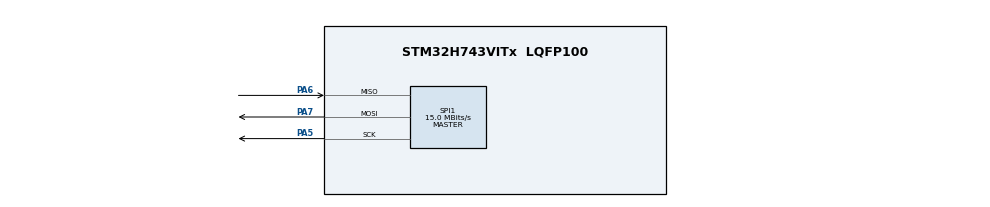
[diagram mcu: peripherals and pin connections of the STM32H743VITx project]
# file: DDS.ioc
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Mcu.Family=STM32H7
Mcu.Name=STM32H743VITx
Mcu.Package=LQFP100
NVIC.PriorityGroup=NVIC_PRIORITYGROUP_4
PA5.Mode=Full_Duplex_Master
PA5.Signal=SPI1_SCK
PA6.Mode=Full_Duplex_Master
PA6.Signal=SPI1_MISO
PA7.Mode=Full_Duplex_Master
PA7.Signal=SPI1_MOSI
PH0-OSC_IN\ (PH0).Mode=HSE-External-Oscillator
PH0-OSC_IN\ (PH0).Signal=RCC_OSC_IN
PH1-OSC_OUT\ (PH1).Mode=HSE-External-Oscillator
PH1-OSC_OUT\ (PH1).Signal=RCC_OSC_OUT
ProjectManager.HeapSize=0x200
ProjectManager.StackSize=0x400
ProjectManager.TargetToolchain=MDK-ARM V5
RCC.ADCFreq_Value=16125000
RCC.APB1Freq_Value=120000000
RCC.APB2Freq_Value=120000000
RCC.APB3Freq_Value=120000000
RCC.APB4Freq_Value=120000000
RCC.CortexFreq_Value=480000000
RCC.D1PPRE=RCC_APB3_DIV2
RCC.D2PPRE1=RCC_APB1_DIV2
RCC.D2PPRE2=RCC_APB2_DIV2
RCC.D3PPRE=RCC_APB4_DIV2
RCC.DIVM1=1
RCC.DIVN1=120
RCC.HCLKFreq_Value=240000000
RCC.HPRE=RCC_HCLK_DIV2
RCC.HSE_VALUE=8000000
RCC.PLL2FRACN=0
RCC.PLL2_VCI_Range-AdvancedSettings=RCC_PLL2VCIRANGE_0
RCC.PLL3FRACN=0
RCC.PLLFRACN=0
RCC.PLLSourceVirtual=RCC_PLLSOURCE_HSE
RCC.SYSCLKFreq_VALUE=480000000
RCC.SYSCLKSource=RCC_SYSCLKSOURCE_PLLCLK
RCC.USBFreq_Value=480000000
SPI1.BaudRatePrescaler=SPI_BAUDRATEPRESCALER_32
SPI1.CalculateBaudRate=15.0 MBits/s
SPI1.DataSize=SPI_DATASIZE_8BIT
SPI1.Direction=SPI_DIRECTION_2LINES
SPI1.Mode=SPI_MODE_MASTER
SPI1.VirtualType=VM_MASTER
board=custom

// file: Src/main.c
/* USER CODE BEGIN Header */
/**
  ******************************************************************************
  * @file           : main.c
  * @brief          : Main program body
  ******************************************************************************
  * @attention
  *
  * <h2><center>&copy; Copyright (c) 2019 STMicroelectronics.
  * All rights reserved.</center></h2>
  *
  * This software component is licensed by ST under BSD 3-Clause license,
  * the "License"; You may not use this file except in compliance with the
  * License. You may obtain a copy of the License at:
  *                        opensource.org/licenses/BSD-3-Clause
  *
  ******************************************************************************
  */
/* USER CODE END Header */

#include "main.h"
#include "spi.h"
#include "gpio.h"

/* USER CODE BEGIN Includes */
#include "ad9910.h"
/* USER CODE END Includes */

void SystemClock_Config(void);

int main(void)
{

  /* MCU Configuration--------------------------------------------------------*/

  /* Reset of all peripherals, Initializes the Flash interface and the Systick. */
  HAL_Init();

  /* Configure the system clock */
  SystemClock_Config();

  /* Initialize all configured peripherals */
  MX_GPIO_Init();
  MX_SPI1_Init();
  /* USER CODE BEGIN 2 */

 AD9910_IO_init();
 ad9910_CR_init();
 IO_Update();

//change_dds_freq_amp_phase(u8 ch, u32 freq, u16 amp, u8 phase);
  /* USER CODE END 2 */

  /* Infinite loop */
  while (1)
  {

  }
}

void SystemClock_Config(void)
{
  RCC_OscInitTypeDef RCC_OscInitStruct = {0};
  RCC_ClkInitTypeDef RCC_ClkInitStruct = {0};
  RCC_PeriphCLKInitTypeDef PeriphClkInitStruct = {0};

  /** Supply configuration update enable
  */
  HAL_PWREx_ConfigSupply(PWR_LDO_SUPPLY);
  /** Configure the main internal regulator output voltage
  */
  __HAL_PWR_VOLTAGESCALING_CONFIG(PWR_REGULATOR_VOLTAGE_SCALE0);

  while(!__HAL_PWR_GET_FLAG(PWR_FLAG_VOSRDY)) {}
  /** Initializes the CPU, AHB and APB busses clocks
  */
  RCC_OscInitStruct.OscillatorType = RCC_OSCILLATORTYPE_HSE;
  RCC_OscInitStruct.HSEState = RCC_HSE_ON;
  RCC_OscInitStruct.PLL.PLLState = RCC_PLL_ON;
  RCC_OscInitStruct.PLL.PLLSource = RCC_PLLSOURCE_HSE;
  RCC_OscInitStruct.PLL.PLLM = 1;
  RCC_OscInitStruct.PLL.PLLN = 120;
  RCC_OscInitStruct.PLL.PLLP = 2;
  RCC_OscInitStruct.PLL.PLLQ = 2;
  RCC_OscInitStruct.PLL.PLLR = 2;
  RCC_OscInitStruct.PLL.PLLRGE = RCC_PLL1VCIRANGE_3;
  RCC_OscInitStruct.PLL.PLLVCOSEL = RCC_PLL1VCOWIDE;
  RCC_OscInitStruct.PLL.PLLFRACN = 0;
  if (HAL_RCC_OscConfig(&RCC_OscInitStruct) != HAL_OK)
  {
    Error_Handler();
  }
  /** Initializes the CPU, AHB and APB busses clocks
  */
  RCC_ClkInitStruct.ClockType = RCC_CLOCKTYPE_HCLK|RCC_CLOCKTYPE_SYSCLK
                              |RCC_CLOCKTYPE_PCLK1|RCC_CLOCKTYPE_PCLK2
                              |RCC_CLOCKTYPE_D3PCLK1|RCC_CLOCKTYPE_D1PCLK1;
  RCC_ClkInitStruct.SYSCLKSource = RCC_SYSCLKSOURCE_PLLCLK;
  RCC_ClkInitStruct.SYSCLKDivider = RCC_SYSCLK_DIV1;
  RCC_ClkInitStruct.AHBCLKDivider = RCC_HCLK_DIV2;
  RCC_ClkInitStruct.APB3CLKDivider = RCC_APB3_DIV2;
  RCC_ClkInitStruct.APB1CLKDivider = RCC_APB1_DIV2;
  RCC_ClkInitStruct.APB2CLKDivider = RCC_APB2_DIV2;
  RCC_ClkInitStruct.APB4CLKDivider = RCC_APB4_DIV2;

  if (HAL_RCC_ClockConfig(&RCC_ClkInitStruct, FLASH_LATENCY_4) != HAL_OK)
  {
    Error_Handler();
  }
  PeriphClkInitStruct.PeriphClockSelection = RCC_PERIPHCLK_SPI1;
  PeriphClkInitStruct.Spi123ClockSelection = RCC_SPI123CLKSOURCE_PLL;
  if (HAL_RCCEx_PeriphCLKConfig(&PeriphClkInitStruct) != HAL_OK)
  {
    Error_Handler();
  }
}

void Error_Handler(void)
{
}

/************************ (C) COPYRIGHT STMicroelectronics *****END OF FILE****/
